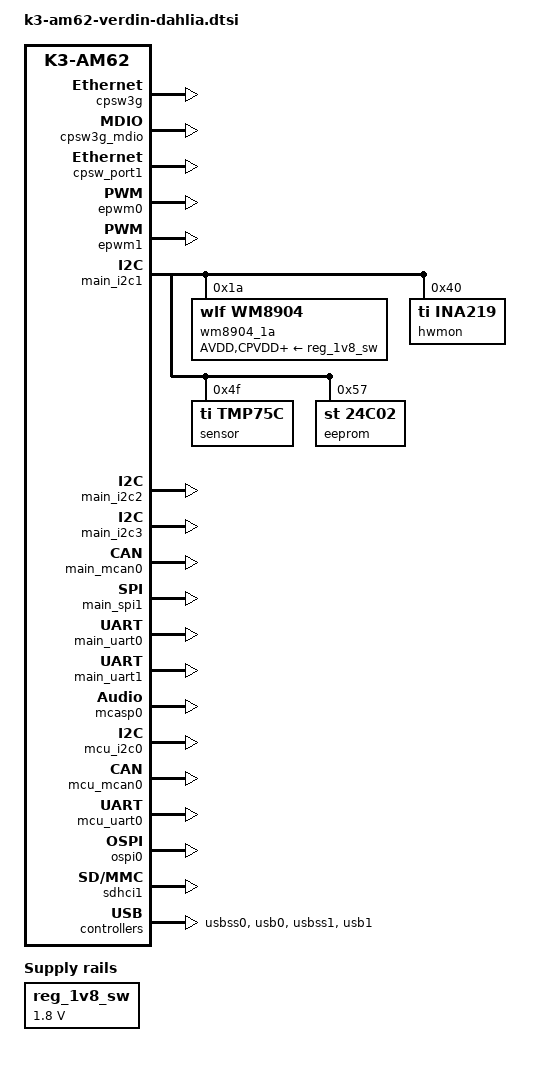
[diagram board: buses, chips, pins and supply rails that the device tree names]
/ {
	reg_1v8_sw: regulator-1v8-sw {
		compatible = "regulator-fixed";
		regulator-max-microvolt = <1800000>;
		regulator-min-microvolt = <1800000>;
		regulator-name = "On-carrier +V1.8_SW";
	};
	sound {
		compatible = "simple-audio-card";
		simple-audio-card,bitclock-master = <&codec_dai>;
		simple-audio-card,format = "i2s";
		simple-audio-card,frame-master = <&codec_dai>;
		simple-audio-card,name = "verdin-wm8904";
		simple-audio-card,routing =
			"Headphone Jack", "HPOUTL",
			"Headphone Jack", "HPOUTR",
			"IN2L", "Line In Jack",
			"IN2R", "Line In Jack",
			"Headphone Jack", "MICBIAS",
			"IN1L", "Headphone Jack";
		simple-audio-card,widgets =
			"Microphone", "Headphone Jack",
			"Headphone", "Headphone Jack",
			"Line", "Line In Jack";
		codec_dai: simple-audio-card,codec {
			clocks = <&audio_refclk1>;
			sound-dai = <&wm8904_1a>;
		};
		simple-audio-card,cpu {
			sound-dai = <&mcasp0>;
		};
	};
};
&cpsw3g {
	status = "okay";
};
&cpsw3g_mdio {
	status = "okay";
};
&cpsw_port1 {
	status = "okay";
};
&epwm0 {
	status = "okay";
};
&epwm1 {
	status = "okay";
};
&main_gpio0 {
	pinctrl-names = "default";
	pinctrl-0 = <&pinctrl_ctrl_sleep_moci>,
		    <&pinctrl_gpio_5>,
		    <&pinctrl_gpio_6>,
		    <&pinctrl_gpio_7>,
		    <&pinctrl_gpio_8>;
};
&main_i2c1 {
	status = "okay";
	wm8904_1a: audio-codec@1a {
		compatible = "wlf,wm8904";
		reg = <0x1a>;
		pinctrl-names = "default";
		pinctrl-0 = <&pinctrl_i2s1_mclk>;
		#sound-dai-cells = <0>;
		clocks = <&audio_refclk1>;
		clock-names = "mclk";
		AVDD-supply = <&reg_1v8_sw>;
		CPVDD-supply = <&reg_1v8_sw>;
		DBVDD-supply = <&reg_1v8_sw>;
		DCVDD-supply = <&reg_1v8_sw>;
		MICVDD-supply = <&reg_1v8_sw>;
	};
	hwmon@40 {
		compatible = "ti,ina219";
		reg = <0x40>;
		shunt-resistor = <10000>;
	};
	sensor@4f {
		compatible = "ti,tmp75c";
		reg = <0x4f>;
	};
	eeprom@57 {
		compatible = "st,24c02";
		reg = <0x57>;
		pagesize = <16>;
	};
};
&main_i2c2 {
	status = "okay";
};
&main_i2c3 {
	status = "okay";
};
&main_mcan0 {
	status = "okay";
};
&main_spi1 {
	status = "okay";
};
&main_uart0 {
	status = "okay";
};
&main_uart1 {
	status = "okay";
};
&mcasp0 {
	status = "okay";
};
&mcu_gpio0 {
	pinctrl-names = "default";
	pinctrl-0 = <&pinctrl_gpio_1>,
		    <&pinctrl_gpio_2>,
		    <&pinctrl_gpio_3>,
		    <&pinctrl_gpio_4>;
};
&mcu_i2c0 {
	status = "okay";
};
&mcu_mcan0 {
	status = "okay";
};
&mcu_uart0 {
	status = "okay";
};
&ospi0 {
	status = "okay";
};
&sdhci1 {
	ti,driver-strength-ohm = <33>;
	status = "okay";
};
&usbss0 {
	status = "okay";
};
&usb0 {
	status = "okay";
};
&usbss1 {
	status = "okay";
};
&usb1 {
	status = "okay";
};
&verdin_gpio_keys {
	status = "okay";
};
&wkup_uart0 {
	status = "reserved";
};
